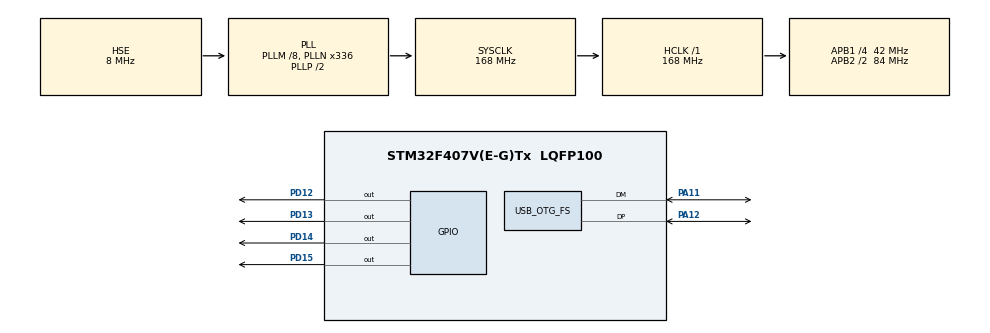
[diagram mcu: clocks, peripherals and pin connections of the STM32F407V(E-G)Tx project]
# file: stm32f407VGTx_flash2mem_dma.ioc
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Dma.MEMTOMEM.0.Direction=DMA_MEMORY_TO_MEMORY
Dma.MEMTOMEM.0.FIFOMode=DMA_FIFOMODE_ENABLE
Dma.MEMTOMEM.0.FIFOThreshold=DMA_FIFO_THRESHOLD_FULL
Dma.MEMTOMEM.0.Instance=DMA2_Stream0
Dma.MEMTOMEM.0.MemBurst=DMA_MBURST_SINGLE
Dma.MEMTOMEM.0.MemDataAlignment=DMA_MDATAALIGN_BYTE
Dma.MEMTOMEM.0.MemInc=DMA_MINC_ENABLE
Dma.MEMTOMEM.0.Mode=DMA_NORMAL
Dma.MEMTOMEM.0.PeriphBurst=DMA_PBURST_SINGLE
Dma.MEMTOMEM.0.PeriphDataAlignment=DMA_PDATAALIGN_BYTE
Dma.MEMTOMEM.0.PeriphInc=DMA_PINC_ENABLE
Dma.MEMTOMEM.0.Priority=DMA_PRIORITY_LOW
Dma.Request0=MEMTOMEM
Mcu.Family=STM32F4
Mcu.Name=STM32F407V(E-G)Tx
Mcu.Package=LQFP100
NVIC.DMA2_Stream0_IRQn=true\:0\:0\:false\:false\:true\:true\:true
NVIC.OTG_FS_IRQn=true\:0\:0\:false\:false\:true\:true\:true
NVIC.PriorityGroup=NVIC_PRIORITYGROUP_0
PA11.Mode=Device_Only
PA11.Signal=USB_OTG_FS_DM
PA12.Mode=Device_Only
PA12.Signal=USB_OTG_FS_DP
PD12.Signal=GPIO_Output
PD13.Signal=GPIO_Output
PD14.Signal=GPIO_Output
PD15.Signal=GPIO_Output
PH0-OSC_IN.Mode=HSE-External-Oscillator
PH0-OSC_IN.Signal=RCC_OSC_IN
PH1-OSC_OUT.Mode=HSE-External-Oscillator
PH1-OSC_OUT.Signal=RCC_OSC_OUT
ProjectManager.HeapSize=0x200
ProjectManager.StackSize=0x400
ProjectManager.TargetToolchain=TrueSTUDIO
RCC.48MHZClocksFreq_Value=48000000
RCC.AHBFreq_Value=168000000
RCC.APB1CLKDivider=RCC_HCLK_DIV4
RCC.APB1Freq_Value=42000000
RCC.APB1TimFreq_Value=84000000
RCC.APB2CLKDivider=RCC_HCLK_DIV2
RCC.APB2Freq_Value=84000000
RCC.APB2TimFreq_Value=168000000
RCC.CortexFreq_Value=168000000
RCC.HCLKFreq_Value=168000000
RCC.HSE_VALUE=8000000
RCC.HSI_VALUE=16000000
RCC.PLLM=8
RCC.PLLN=336
RCC.PLLQ=7
RCC.SYSCLKFreq_VALUE=168000000
RCC.SYSCLKSource=RCC_SYSCLKSOURCE_PLLCLK
RCC.VCOOutputFreq_Value=336000000
USB_DEVICE.CLASS_NAME_FS=CDC
USB_DEVICE.VirtualMode-CDC_FS=Cdc
USB_DEVICE.VirtualModeFS=Cdc_FS
USB_OTG_FS.VirtualMode=Device_Only
VP_USB_DEVICE_VS_USB_DEVICE_CDC_FS.Mode=CDC_FS
board=STM32F407G-DISC1

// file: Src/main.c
/* USER CODE BEGIN Header */
/**
  ******************************************************************************
  * @file           : main.c
  * @brief          : Main program body
  ******************************************************************************
  * @attention
  *
  * <h2><center>&copy; Copyright (c) 2019 STMicroelectronics.
  * All rights reserved.</center></h2>
  *
  * This software component is licensed by ST under Ultimate Liberty license
  * SLA0044, the "License"; You may not use this file except in compliance with
  * the License. You may obtain a copy of the License at:
  *                             www.st.com/SLA0044
  *
  ******************************************************************************
  */
/* USER CODE END Header */

#include "main.h"
#include "usb_device.h"

/* USER CODE BEGIN Includes */
#include "usbd_cdc_if.h"
#include "dma_flash.h"
#include <string.h>
/* USER CODE END Includes */

DMA_HandleTypeDef hdma_memtomem_dma2_stream0;

void SystemClock_Config(void);
static void MX_GPIO_Init(void);
static void MX_DMA_Init(void);

int main(void)
{

  /* MCU Configuration--------------------------------------------------------*/

  /* Reset of all peripherals, Initializes the Flash interface and the Systick. */
  HAL_Init();

  /* Configure the system clock */
  SystemClock_Config();

  /* Initialize all configured peripherals */
  MX_GPIO_Init();
  MX_USB_DEVICE_Init();
  MX_DMA_Init();
  /* USER CODE BEGIN 2 */
  dma_flash2mem();
  /* USER CODE END 2 */

  /* Infinite loop */
  while (1)
  {

    /* USER CODE BEGIN 3 */
	HAL_GPIO_TogglePin(GPIOD, GPIO_PIN_12);
	HAL_Delay(200);
	dma_flash2mem_done();
  }
  /* USER CODE END 3 */
}

void SystemClock_Config(void)
{
  RCC_OscInitTypeDef RCC_OscInitStruct = {0};
  RCC_ClkInitTypeDef RCC_ClkInitStruct = {0};

  /** Configure the main internal regulator output voltage
  */
  __HAL_RCC_PWR_CLK_ENABLE();
  __HAL_PWR_VOLTAGESCALING_CONFIG(PWR_REGULATOR_VOLTAGE_SCALE1);
  /** Initializes the CPU, AHB and APB busses clocks
  */
  RCC_OscInitStruct.OscillatorType = RCC_OSCILLATORTYPE_HSE;
  RCC_OscInitStruct.HSEState = RCC_HSE_ON;
  RCC_OscInitStruct.PLL.PLLState = RCC_PLL_ON;
  RCC_OscInitStruct.PLL.PLLSource = RCC_PLLSOURCE_HSE;
  RCC_OscInitStruct.PLL.PLLM = 8;
  RCC_OscInitStruct.PLL.PLLN = 336;
  RCC_OscInitStruct.PLL.PLLP = RCC_PLLP_DIV2;
  RCC_OscInitStruct.PLL.PLLQ = 7;
  if (HAL_RCC_OscConfig(&RCC_OscInitStruct) != HAL_OK)
  {
    Error_Handler();
  }
  /** Initializes the CPU, AHB and APB busses clocks
  */
  RCC_ClkInitStruct.ClockType = RCC_CLOCKTYPE_HCLK|RCC_CLOCKTYPE_SYSCLK
                              |RCC_CLOCKTYPE_PCLK1|RCC_CLOCKTYPE_PCLK2;
  RCC_ClkInitStruct.SYSCLKSource = RCC_SYSCLKSOURCE_PLLCLK;
  RCC_ClkInitStruct.AHBCLKDivider = RCC_SYSCLK_DIV1;
  RCC_ClkInitStruct.APB1CLKDivider = RCC_HCLK_DIV4;
  RCC_ClkInitStruct.APB2CLKDivider = RCC_HCLK_DIV2;

  if (HAL_RCC_ClockConfig(&RCC_ClkInitStruct, FLASH_LATENCY_5) != HAL_OK)
  {
    Error_Handler();
  }
}

static void MX_DMA_Init(void)
{

  /* DMA controller clock enable */
  __HAL_RCC_DMA2_CLK_ENABLE();

  /* Configure DMA request hdma_memtomem_dma2_stream0 on DMA2_Stream0 */
  hdma_memtomem_dma2_stream0.Instance = DMA2_Stream0;
  hdma_memtomem_dma2_stream0.Init.Channel = DMA_CHANNEL_0;
  hdma_memtomem_dma2_stream0.Init.Direction = DMA_MEMORY_TO_MEMORY;
  hdma_memtomem_dma2_stream0.Init.PeriphInc = DMA_PINC_ENABLE;
  hdma_memtomem_dma2_stream0.Init.MemInc = DMA_MINC_ENABLE;
  hdma_memtomem_dma2_stream0.Init.PeriphDataAlignment = DMA_PDATAALIGN_BYTE;
  hdma_memtomem_dma2_stream0.Init.MemDataAlignment = DMA_MDATAALIGN_BYTE;
  hdma_memtomem_dma2_stream0.Init.Mode = DMA_NORMAL;
  hdma_memtomem_dma2_stream0.Init.Priority = DMA_PRIORITY_LOW;
  hdma_memtomem_dma2_stream0.Init.FIFOMode = DMA_FIFOMODE_ENABLE;
  hdma_memtomem_dma2_stream0.Init.FIFOThreshold = DMA_FIFO_THRESHOLD_FULL;
  hdma_memtomem_dma2_stream0.Init.MemBurst = DMA_MBURST_SINGLE;
  hdma_memtomem_dma2_stream0.Init.PeriphBurst = DMA_PBURST_SINGLE;
  if (HAL_DMA_Init(&hdma_memtomem_dma2_stream0) != HAL_OK)
  {
    Error_Handler( );
  }

  /* DMA interrupt init */
  /* DMA2_Stream0_IRQn interrupt configuration */
  HAL_NVIC_SetPriority(DMA2_Stream0_IRQn, 0, 0);
  HAL_NVIC_EnableIRQ(DMA2_Stream0_IRQn);

}

static void MX_GPIO_Init(void)
{
  GPIO_InitTypeDef GPIO_InitStruct = {0};

  /* GPIO Ports Clock Enable */
  __HAL_RCC_GPIOH_CLK_ENABLE();
  __HAL_RCC_GPIOD_CLK_ENABLE();
  __HAL_RCC_GPIOA_CLK_ENABLE();

  /*Configure GPIO pin Output Level */
  HAL_GPIO_WritePin(GPIOD, GPIO_PIN_12|GPIO_PIN_13|GPIO_PIN_14|GPIO_PIN_15, GPIO_PIN_RESET);

  /*Configure GPIO pins : PD12 PD13 PD14 PD15 */
  GPIO_InitStruct.Pin = GPIO_PIN_12|GPIO_PIN_13|GPIO_PIN_14|GPIO_PIN_15;
  GPIO_InitStruct.Mode = GPIO_MODE_OUTPUT_PP;
  GPIO_InitStruct.Pull = GPIO_NOPULL;
  GPIO_InitStruct.Speed = GPIO_SPEED_FREQ_LOW;
  HAL_GPIO_Init(GPIOD, &GPIO_InitStruct);

}

void Error_Handler(void)
{
}

/************************ (C) COPYRIGHT STMicroelectronics *****END OF FILE****/
